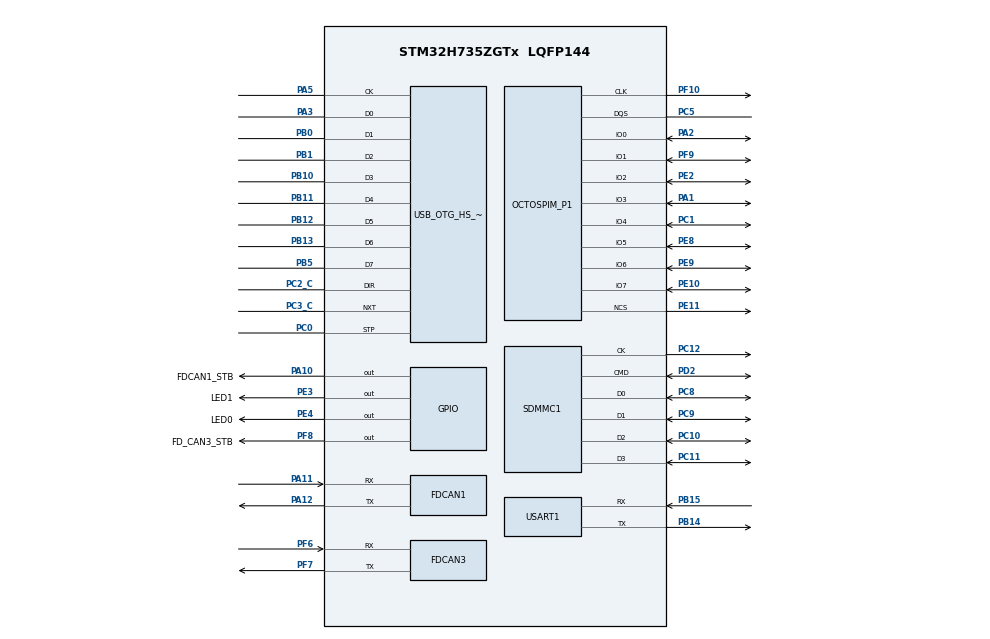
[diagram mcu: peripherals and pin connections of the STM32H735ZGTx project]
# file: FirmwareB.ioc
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Mcu.Family=STM32H7
NVIC.OTG_HS_IRQn=true\:5\:0\:false\:false\:true\:true\:false\:true
PH0-OSC_IN.Signal=RCC_OSC_IN
VP_USB_DEVICE_VS_USB_DEVICE_CDC_HS.Mode=CDC_HS
RCC.CortexFreq_Value=550000000
FATFS._USE_LFN=2
PB10.Mode=Device_HS
RCC.HPRE=RCC_HCLK_DIV2
VP_FATFS_VS_SDIO.Mode=SDIO
PA15(JTDI).Signal=DEBUG_JTDI
PC10.Signal=SDMMC1_D2
PC12.Signal=SDMMC1_CK
RCC.PLLFRACN=6144
PC3_C.Mode=Device_HS
PA13(JTMS/SWDIO).Signal=DEBUG_JTMS-SWDIO
VP_RTC_VS_RTC_Activate.Mode=RTC_Enabled
PA11.Mode=FDCAN_Activate
NVIC.TIM1_UP_IRQn=true\:0\:0\:false\:false\:true\:false\:false\:true
RCC.PLL2FRACN=0
PC5.Mode=OCTOSPI1_Port1_DQS
PB11.Signal=USB_OTG_HS_ULPI_D4
PB13.Signal=USB_OTG_HS_ULPI_D6
PB15.Signal=USART1_RX
PB4(NJTRST).Mode=JTAG_5_pins
USB_OTG_HS.VirtualMode-Device_HS=Device_HS
RCC.SYSCLKSource=RCC_SYSCLKSOURCE_PLLCLK
ProjectManager.StackSize=0x400
VP_FREERTOS_VS_CMSIS_V2.Mode=CMSIS_V2
PA13(JTMS/SWDIO).Mode=JTAG_5_pins
PA12.Signal=FDCAN1_TX
PE11.Mode=OCTOSPI1_Port1_NCS
PF7.Signal=FDCAN3_TX
RCC.HCLKFreq_Value=275000000
PE2.Mode=OCTOSPI1_IOL_Port1L
PC2_C.Signal=USB_OTG_HS_ULPI_DIR
PH0-OSC_IN.Mode=HSE-External-Oscillator
RCC.HSE_VALUE=8000000
RCC.DIVM1=1
RCC.RTCClockSelection=RCC_RTCCLKSOURCE_LSE
PF9.Mode=OCTOSPI1_IOL_Port1L
PC14-OSC32_IN.Mode=LSE-External-Oscillator
PE9.Signal=OCTOSPIM_P1_IO6
PB14.Mode=Asynchronous
VP_SYS_VS_tim1.Mode=TIM1
PB3(JTDO/TRACESWO).Signal=DEBUG_JTDO-SWO
PB5.Mode=Device_HS
PA10.GPIO_Label=FDCAN1_STB
PE4.GPIO_Label=LED0
PC9.Mode=SD_4_bits_Wide_bus
PE2.Signal=OCTOSPIM_P1_IO2
PE4.Signal=GPIO_Output
PE10.Signal=OCTOSPIM_P1_IO7
RCC.APB3Freq_Value=137500000
PH1-OSC_OUT.Mode=HSE-External-Oscillator
Mcu.Package=LQFP144
PB1.Signal=USB_OTG_HS_ULPI_D2
PB12.Mode=Device_HS
NVIC.TimeBase=TIM1_UP_IRQn
RCC.PLL3FRACN=0
RCC.D1PPRE=RCC_APB3_DIV2
PB3(JTDO/TRACESWO).Mode=JTAG_5_pins
NVIC.TimeBaseIP=TIM1
PA10.Signal=GPIO_Output
USB_DEVICE.CLASS_NAME_HS=CDC
PF8.Signal=GPIO_Output
PE9.Mode=OCTOSPI1_IOH_Port1H
PC11.Mode=SD_4_bits_Wide_bus
USB_DEVICE.VirtualModeHS=Cdc_HS
RCC.APB4Freq_Value=137500000
PF10.Mode=O1_P1_CLK
PC5.Signal=OCTOSPIM_P1_DQS
PB13.Mode=Device_HS
PA3.Signal=USB_OTG_HS_ULPI_D0
PA5.Mode=Device_HS
PC15-OSC32_OUT.Mode=LSE-External-Oscillator
RCC.DIVQ1=5
FREERTOS.Tasks01=defaultTask,24,128,StartDefaultTask,Default,NULL,Static,defaultTaskBuffer,defaultTaskControlBlock
FATFS._USE_MUTEX=1
PC11.Signal=SDMMC1_D3
PC8.Signal=SDMMC1_D0
PE10.Mode=OCTOSPI1_IOH_Port1H
PC10.Mode=SD_4_bits_Wide_bus
RCC.D2PPRE2=RCC_APB2_DIV2
RCC.D2PPRE1=RCC_APB1_DIV2
RCC.DIVP1=1
PC0.Signal=USB_OTG_HS_ULPI_STP
PC14-OSC32_IN.Signal=RCC_OSC32_IN
PB4(NJTRST).Signal=DEBUG_JTRST
PC0.Mode=Device_HS
PF8.GPIO_Label=FD_CAN3_STB
PE8.Mode=OCTOSPI1_IOH_Port1H
USART1.VirtualMode-Asynchronous=VM_ASYNC
PA3.Mode=Device_HS
PF7.Mode=FDCAN_Activate
PF6.Signal=FDCAN3_RX
PB11.Mode=Device_HS
ProjectManager.TargetToolchain=STM32CubeIDE
RCC.DIVN1=68
PC2_C.Mode=Device_HS
RCC.USBFreq_Value=110000000
PE11.Signal=OCTOSPIM_P1_NCS
PC15-OSC32_OUT.Signal=RCC_OSC32_OUT
PA1.Signal=OCTOSPIM_P1_IO3
PB10.Signal=USB_OTG_HS_ULPI_D3
PB14.Signal=USART1_TX
PD2.Mode=SD_4_bits_Wide_bus
PA5.Signal=USB_OTG_HS_ULPI_CK
PC12.Mode=SD_4_bits_Wide_bus
PB0.Mode=Device_HS
board=custom
PB15.Mode=Asynchronous
RCC.APB2Freq_Value=137500000
PA1.Mode=OCTOSPI1_IOL_Port1L
FATFS._FS_EXFAT=1
VP_TIM2_VS_ClockSourceINT.Mode=Internal
PE8.Signal=OCTOSPIM_P1_IO5
PF10.Signal=OCTOSPIM_P1_CLK
RCC.ADCFreq_Value=16125000
PH1-OSC_OUT.Signal=RCC_OSC_OUT
PA14(JTCK/SWCLK).Mode=JTAG_5_pins
Mcu.Name=STM32H735ZGTx
PA2.Signal=OCTOSPIM_P1_IO0
PC8.Mode=SD_4_bits_Wide_bus
RCC.SYSCLKFreq_VALUE=550000000
PB5.Signal=USB_OTG_HS_ULPI_D7
PA12.Mode=FDCAN_Activate
VP_OCTOSPI1_VS_hyperbus.Mode=hyperbus_mode
PA11.Signal=FDCAN1_RX
ProjectManager.HeapSize=0x200
PB1.Mode=Device_HS
PF6.Mode=FDCAN_Activate
PF9.Signal=OCTOSPIM_P1_IO1
NVIC.PriorityGroup=NVIC_PRIORITYGROUP_4
PC3_C.Signal=USB_OTG_HS_ULPI_NXT
PE3.Signal=GPIO_Output
PA2.Mode=OCTOSPI1_IOL_Port1L
PE3.GPIO_Label=LED1
RCC.D3PPRE=RCC_APB4_DIV2
PA14(JTCK/SWCLK).Signal=DEBUG_JTCK-SWCLK
PC9.Signal=SDMMC1_D1
PA15(JTDI).Mode=JTAG_5_pins
PD2.Signal=SDMMC1_CMD
RCC.APB1Freq_Value=137500000
PB0.Signal=USB_OTG_HS_ULPI_D1
USB_DEVICE.VirtualMode=Cdc
PC1.Signal=OCTOSPIM_P1_IO4
PB12.Signal=USB_OTG_HS_ULPI_D5
PC1.Mode=OCTOSPI1_IOH_Port1H

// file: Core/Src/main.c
/* USER CODE BEGIN Header */
/**
  ******************************************************************************
  * @file           : main.c
  * @brief          : Main program body
  ******************************************************************************
  * @attention
  *
  * <h2><center>&copy; Copyright (c) 2021 STMicroelectronics.
  * All rights reserved.</center></h2>
  *
  * This software component is licensed by ST under Ultimate Liberty license
  * SLA0044, the "License"; You may not use this file except in compliance with
  * the License. You may obtain a copy of the License at:
  *                             www.st.com/SLA0044
  *
  ******************************************************************************
  */
/* USER CODE END Header */
#include "main.h"
#include "cmsis_os.h"
#include "fatfs.h"
#include "usb_device.h"

typedef StaticTask_t osStaticThreadDef_t;

FDCAN_HandleTypeDef hfdcan1;
FDCAN_HandleTypeDef hfdcan3;

OSPI_HandleTypeDef hospi1;

RTC_HandleTypeDef hrtc;

SD_HandleTypeDef hsd1;

TIM_HandleTypeDef htim2;

UART_HandleTypeDef huart1;

/* Definitions for defaultTask */
osThreadId_t defaultTaskHandle;
uint32_t defaultTaskBuffer[ 128 ];
osStaticThreadDef_t defaultTaskControlBlock;
const osThreadAttr_t defaultTask_attributes = {
  .name = "defaultTask",
  .cb_mem = &defaultTaskControlBlock,
  .cb_size = sizeof(defaultTaskControlBlock),
  .stack_mem = &defaultTaskBuffer[0],
  .stack_size = sizeof(defaultTaskBuffer),
  .priority = (osPriority_t) osPriorityNormal,
};

void SystemClock_Config(void);
static void MX_GPIO_Init(void);
static void MX_FDCAN1_Init(void);
static void MX_FDCAN3_Init(void);
static void MX_OCTOSPI1_Init(void);
static void MX_SDMMC1_SD_Init(void);
static void MX_USART1_UART_Init(void);
static void MX_RTC_Init(void);
static void MX_TIM2_Init(void);
void StartDefaultTask(void *argument);

int main(void)
{

  /* MCU Configuration--------------------------------------------------------*/

  /* Reset of all peripherals, Initializes the Flash interface and the Systick. */
  HAL_Init();

  /* Configure the system clock */
  SystemClock_Config();

  /* Initialize all configured peripherals */
  MX_GPIO_Init();
  MX_FDCAN1_Init();
  MX_FDCAN3_Init();
  MX_OCTOSPI1_Init();
  MX_SDMMC1_SD_Init();
  MX_USART1_UART_Init();
  MX_RTC_Init();
  MX_FATFS_Init();
  MX_TIM2_Init();

  /* Init scheduler */
  osKernelInitialize();

  /* Create the thread(s) */
  /* creation of defaultTask */
  defaultTaskHandle = osThreadNew(StartDefaultTask, NULL, &defaultTask_attributes);

  /* Start scheduler */
  osKernelStart();

  /* We should never get here as control is now taken by the scheduler */
  /* Infinite loop */
  while (1)
  {

  }
}

void SystemClock_Config(void)
{
  RCC_OscInitTypeDef RCC_OscInitStruct = {0};
  RCC_ClkInitTypeDef RCC_ClkInitStruct = {0};

  /** Supply configuration update enable
  */
  HAL_PWREx_ConfigSupply(PWR_LDO_SUPPLY);
  /** Configure the main internal regulator output voltage
  */
  __HAL_PWR_VOLTAGESCALING_CONFIG(PWR_REGULATOR_VOLTAGE_SCALE0);

  while(!__HAL_PWR_GET_FLAG(PWR_FLAG_VOSRDY)) {}
  /** Configure LSE Drive Capability
  */
  HAL_PWR_EnableBkUpAccess();
  __HAL_RCC_LSEDRIVE_CONFIG(RCC_LSEDRIVE_LOW);
  /** Initializes the RCC Oscillators according to the specified parameters
  * in the RCC_OscInitTypeDef structure.
  */
  RCC_OscInitStruct.OscillatorType = RCC_OSCILLATORTYPE_HSE|RCC_OSCILLATORTYPE_LSE;
  RCC_OscInitStruct.HSEState = RCC_HSE_ON;
  RCC_OscInitStruct.LSEState = RCC_LSE_ON;
  RCC_OscInitStruct.PLL.PLLState = RCC_PLL_ON;
  RCC_OscInitStruct.PLL.PLLSource = RCC_PLLSOURCE_HSE;
  RCC_OscInitStruct.PLL.PLLM = 1;
  RCC_OscInitStruct.PLL.PLLN = 68;
  RCC_OscInitStruct.PLL.PLLP = 1;
  RCC_OscInitStruct.PLL.PLLQ = 5;
  RCC_OscInitStruct.PLL.PLLR = 2;
  RCC_OscInitStruct.PLL.PLLRGE = RCC_PLL1VCIRANGE_3;
  RCC_OscInitStruct.PLL.PLLVCOSEL = RCC_PLL1VCOWIDE;
  RCC_OscInitStruct.PLL.PLLFRACN = 6144;
  if (HAL_RCC_OscConfig(&RCC_OscInitStruct) != HAL_OK)
  {
    Error_Handler();
  }
  /** Initializes the CPU, AHB and APB buses clocks
  */
  RCC_ClkInitStruct.ClockType = RCC_CLOCKTYPE_HCLK|RCC_CLOCKTYPE_SYSCLK
                              |RCC_CLOCKTYPE_PCLK1|RCC_CLOCKTYPE_PCLK2
                              |RCC_CLOCKTYPE_D3PCLK1|RCC_CLOCKTYPE_D1PCLK1;
  RCC_ClkInitStruct.SYSCLKSource = RCC_SYSCLKSOURCE_PLLCLK;
  RCC_ClkInitStruct.SYSCLKDivider = RCC_SYSCLK_DIV1;
  RCC_ClkInitStruct.AHBCLKDivider = RCC_HCLK_DIV2;
  RCC_ClkInitStruct.APB3CLKDivider = RCC_APB3_DIV2;
  RCC_ClkInitStruct.APB1CLKDivider = RCC_APB1_DIV2;
  RCC_ClkInitStruct.APB2CLKDivider = RCC_APB2_DIV2;
  RCC_ClkInitStruct.APB4CLKDivider = RCC_APB4_DIV2;

  if (HAL_RCC_ClockConfig(&RCC_ClkInitStruct, FLASH_LATENCY_3) != HAL_OK)
  {
    Error_Handler();
  }
}

static void MX_FDCAN1_Init(void)
{

  hfdcan1.Instance = FDCAN1;
  hfdcan1.Init.FrameFormat = FDCAN_FRAME_CLASSIC;
  hfdcan1.Init.Mode = FDCAN_MODE_NORMAL;
  hfdcan1.Init.AutoRetransmission = DISABLE;
  hfdcan1.Init.TransmitPause = DISABLE;
  hfdcan1.Init.ProtocolException = DISABLE;
  hfdcan1.Init.NominalPrescaler = 1;
  hfdcan1.Init.NominalSyncJumpWidth = 1;
  hfdcan1.Init.NominalTimeSeg1 = 2;
  hfdcan1.Init.NominalTimeSeg2 = 2;
  hfdcan1.Init.DataPrescaler = 1;
  hfdcan1.Init.DataSyncJumpWidth = 1;
  hfdcan1.Init.DataTimeSeg1 = 1;
  hfdcan1.Init.DataTimeSeg2 = 1;
  hfdcan1.Init.MessageRAMOffset = 0;
  hfdcan1.Init.StdFiltersNbr = 0;
  hfdcan1.Init.ExtFiltersNbr = 0;
  hfdcan1.Init.RxFifo0ElmtsNbr = 0;
  hfdcan1.Init.RxFifo0ElmtSize = FDCAN_DATA_BYTES_8;
  hfdcan1.Init.RxFifo1ElmtsNbr = 0;
  hfdcan1.Init.RxFifo1ElmtSize = FDCAN_DATA_BYTES_8;
  hfdcan1.Init.RxBuffersNbr = 0;
  hfdcan1.Init.RxBufferSize = FDCAN_DATA_BYTES_8;
  hfdcan1.Init.TxEventsNbr = 0;
  hfdcan1.Init.TxBuffersNbr = 0;
  hfdcan1.Init.TxFifoQueueElmtsNbr = 0;
  hfdcan1.Init.TxFifoQueueMode = FDCAN_TX_FIFO_OPERATION;
  hfdcan1.Init.TxElmtSize = FDCAN_DATA_BYTES_8;
  if (HAL_FDCAN_Init(&hfdcan1) != HAL_OK)
  {
    Error_Handler();
  }

}

static void MX_FDCAN3_Init(void)
{

  hfdcan3.Instance = FDCAN3;
  hfdcan3.Init.FrameFormat = FDCAN_FRAME_CLASSIC;
  hfdcan3.Init.Mode = FDCAN_MODE_NORMAL;
  hfdcan3.Init.AutoRetransmission = DISABLE;
  hfdcan3.Init.TransmitPause = DISABLE;
  hfdcan3.Init.ProtocolException = DISABLE;
  hfdcan3.Init.NominalPrescaler = 1;
  hfdcan3.Init.NominalSyncJumpWidth = 1;
  hfdcan3.Init.NominalTimeSeg1 = 2;
  hfdcan3.Init.NominalTimeSeg2 = 2;
  hfdcan3.Init.DataPrescaler = 1;
  hfdcan3.Init.DataSyncJumpWidth = 1;
  hfdcan3.Init.DataTimeSeg1 = 1;
  hfdcan3.Init.DataTimeSeg2 = 1;
  hfdcan3.Init.MessageRAMOffset = 0;
  hfdcan3.Init.StdFiltersNbr = 0;
  hfdcan3.Init.ExtFiltersNbr = 0;
  hfdcan3.Init.RxFifo0ElmtsNbr = 0;
  hfdcan3.Init.RxFifo0ElmtSize = FDCAN_DATA_BYTES_8;
  hfdcan3.Init.RxFifo1ElmtsNbr = 0;
  hfdcan3.Init.RxFifo1ElmtSize = FDCAN_DATA_BYTES_8;
  hfdcan3.Init.RxBuffersNbr = 0;
  hfdcan3.Init.RxBufferSize = FDCAN_DATA_BYTES_8;
  hfdcan3.Init.TxEventsNbr = 0;
  hfdcan3.Init.TxBuffersNbr = 0;
  hfdcan3.Init.TxFifoQueueElmtsNbr = 0;
  hfdcan3.Init.TxFifoQueueMode = FDCAN_TX_FIFO_OPERATION;
  hfdcan3.Init.TxElmtSize = FDCAN_DATA_BYTES_8;
  if (HAL_FDCAN_Init(&hfdcan3) != HAL_OK)
  {
    Error_Handler();
  }

}

static void MX_OCTOSPI1_Init(void)
{

  OSPIM_CfgTypeDef sOspiManagerCfg = {0};
  OSPI_HyperbusCfgTypeDef sHyperBusCfg = {0};

  /* OCTOSPI1 parameter configuration*/
  hospi1.Instance = OCTOSPI1;
  hospi1.Init.FifoThreshold = 1;
  hospi1.Init.DualQuad = HAL_OSPI_DUALQUAD_DISABLE;
  hospi1.Init.MemoryType = HAL_OSPI_MEMTYPE_HYPERBUS;
  hospi1.Init.DeviceSize = 32;
  hospi1.Init.ChipSelectHighTime = 1;
  hospi1.Init.FreeRunningClock = HAL_OSPI_FREERUNCLK_DISABLE;
  hospi1.Init.ClockMode = HAL_OSPI_CLOCK_MODE_0;
  hospi1.Init.WrapSize = HAL_OSPI_WRAP_NOT_SUPPORTED;
  hospi1.Init.ClockPrescaler = 1;
  hospi1.Init.SampleShifting = HAL_OSPI_SAMPLE_SHIFTING_NONE;
  hospi1.Init.DelayHoldQuarterCycle = HAL_OSPI_DHQC_DISABLE;
  hospi1.Init.ChipSelectBoundary = 1;
  hospi1.Init.ClkChipSelectHighTime = 0;
  hospi1.Init.DelayBlockBypass = HAL_OSPI_DELAY_BLOCK_BYPASSED;
  hospi1.Init.MaxTran = 0;
  hospi1.Init.Refresh = 0;
  if (HAL_OSPI_Init(&hospi1) != HAL_OK)
  {
    Error_Handler();
  }
  sOspiManagerCfg.ClkPort = 1;
  sOspiManagerCfg.DQSPort = 1;
  sOspiManagerCfg.NCSPort = 1;
  sOspiManagerCfg.IOLowPort = HAL_OSPIM_IOPORT_1_LOW;
  sOspiManagerCfg.IOHighPort = HAL_OSPIM_IOPORT_1_HIGH;
  if (HAL_OSPIM_Config(&hospi1, &sOspiManagerCfg, HAL_OSPI_TIMEOUT_DEFAULT_VALUE) != HAL_OK)
  {
    Error_Handler();
  }
  sHyperBusCfg.RWRecoveryTime = 0;
  sHyperBusCfg.AccessTime = 0;
  sHyperBusCfg.WriteZeroLatency = HAL_OSPI_NO_LATENCY_ON_WRITE;
  sHyperBusCfg.LatencyMode = HAL_OSPI_VARIABLE_LATENCY;
  if (HAL_OSPI_HyperbusCfg(&hospi1, &sHyperBusCfg, HAL_OSPI_TIMEOUT_DEFAULT_VALUE) != HAL_OK)
  {
    Error_Handler();
  }

}

static void MX_RTC_Init(void)
{

  /** Initialize RTC Only
  */
  hrtc.Instance = RTC;
  hrtc.Init.HourFormat = RTC_HOURFORMAT_24;
  hrtc.Init.AsynchPrediv = 127;
  hrtc.Init.SynchPrediv = 255;
  hrtc.Init.OutPut = RTC_OUTPUT_DISABLE;
  hrtc.Init.OutPutPolarity = RTC_OUTPUT_POLARITY_HIGH;
  hrtc.Init.OutPutType = RTC_OUTPUT_TYPE_OPENDRAIN;
  hrtc.Init.OutPutRemap = RTC_OUTPUT_REMAP_NONE;
  if (HAL_RTC_Init(&hrtc) != HAL_OK)
  {
    Error_Handler();
  }

}

static void MX_SDMMC1_SD_Init(void)
{

  hsd1.Instance = SDMMC1;
  hsd1.Init.ClockEdge = SDMMC_CLOCK_EDGE_RISING;
  hsd1.Init.ClockPowerSave = SDMMC_CLOCK_POWER_SAVE_DISABLE;
  hsd1.Init.BusWide = SDMMC_BUS_WIDE_4B;
  hsd1.Init.HardwareFlowControl = SDMMC_HARDWARE_FLOW_CONTROL_DISABLE;
  hsd1.Init.ClockDiv = 0;
  hsd1.Init.TranceiverPresent = SDMMC_TRANSCEIVER_NOT_PRESENT;

}

static void MX_TIM2_Init(void)
{

  TIM_ClockConfigTypeDef sClockSourceConfig = {0};
  TIM_MasterConfigTypeDef sMasterConfig = {0};

  htim2.Instance = TIM2;
  htim2.Init.Prescaler = 0;
  htim2.Init.CounterMode = TIM_COUNTERMODE_UP;
  htim2.Init.Period = 4294967295;
  htim2.Init.ClockDivision = TIM_CLOCKDIVISION_DIV1;
  htim2.Init.AutoReloadPreload = TIM_AUTORELOAD_PRELOAD_DISABLE;
  if (HAL_TIM_Base_Init(&htim2) != HAL_OK)
  {
    Error_Handler();
  }
  sClockSourceConfig.ClockSource = TIM_CLOCKSOURCE_INTERNAL;
  if (HAL_TIM_ConfigClockSource(&htim2, &sClockSourceConfig) != HAL_OK)
  {
    Error_Handler();
  }
  sMasterConfig.MasterOutputTrigger = TIM_TRGO_RESET;
  sMasterConfig.MasterSlaveMode = TIM_MASTERSLAVEMODE_DISABLE;
  if (HAL_TIMEx_MasterConfigSynchronization(&htim2, &sMasterConfig) != HAL_OK)
  {
    Error_Handler();
  }

}

static void MX_USART1_UART_Init(void)
{

  huart1.Instance = USART1;
  huart1.Init.BaudRate = 115200;
  huart1.Init.WordLength = UART_WORDLENGTH_8B;
  huart1.Init.StopBits = UART_STOPBITS_1;
  huart1.Init.Parity = UART_PARITY_NONE;
  huart1.Init.Mode = UART_MODE_TX_RX;
  huart1.Init.HwFlowCtl = UART_HWCONTROL_NONE;
  huart1.Init.OverSampling = UART_OVERSAMPLING_16;
  huart1.Init.OneBitSampling = UART_ONE_BIT_SAMPLE_DISABLE;
  huart1.Init.ClockPrescaler = UART_PRESCALER_DIV1;
  huart1.AdvancedInit.AdvFeatureInit = UART_ADVFEATURE_NO_INIT;
  if (HAL_UART_Init(&huart1) != HAL_OK)
  {
    Error_Handler();
  }
  if (HAL_UARTEx_SetTxFifoThreshold(&huart1, UART_TXFIFO_THRESHOLD_1_8) != HAL_OK)
  {
    Error_Handler();
  }
  if (HAL_UARTEx_SetRxFifoThreshold(&huart1, UART_RXFIFO_THRESHOLD_1_8) != HAL_OK)
  {
    Error_Handler();
  }
  if (HAL_UARTEx_DisableFifoMode(&huart1) != HAL_OK)
  {
    Error_Handler();
  }

}

static void MX_GPIO_Init(void)
{
  GPIO_InitTypeDef GPIO_InitStruct = {0};

  /* GPIO Ports Clock Enable */
  __HAL_RCC_GPIOE_CLK_ENABLE();
  __HAL_RCC_GPIOC_CLK_ENABLE();
  __HAL_RCC_GPIOF_CLK_ENABLE();
  __HAL_RCC_GPIOH_CLK_ENABLE();
  __HAL_RCC_GPIOA_CLK_ENABLE();
  __HAL_RCC_GPIOB_CLK_ENABLE();
  __HAL_RCC_GPIOD_CLK_ENABLE();

  /*Configure GPIO pin Output Level */
  HAL_GPIO_WritePin(GPIOE, LED1_Pin|LED0_Pin, GPIO_PIN_RESET);

  /*Configure GPIO pin Output Level */
  HAL_GPIO_WritePin(FD_CAN3_STB_GPIO_Port, FD_CAN3_STB_Pin, GPIO_PIN_RESET);

  /*Configure GPIO pin Output Level */
  HAL_GPIO_WritePin(FDCAN1_STB_GPIO_Port, FDCAN1_STB_Pin, GPIO_PIN_RESET);

  /*Configure GPIO pins : LED1_Pin LED0_Pin */
  GPIO_InitStruct.Pin = LED1_Pin|LED0_Pin;
  GPIO_InitStruct.Mode = GPIO_MODE_OUTPUT_PP;
  GPIO_InitStruct.Pull = GPIO_NOPULL;
  GPIO_InitStruct.Speed = GPIO_SPEED_FREQ_LOW;
  HAL_GPIO_Init(GPIOE, &GPIO_InitStruct);

  /*Configure GPIO pin : FD_CAN3_STB_Pin */
  GPIO_InitStruct.Pin = FD_CAN3_STB_Pin;
  GPIO_InitStruct.Mode = GPIO_MODE_OUTPUT_PP;
  GPIO_InitStruct.Pull = GPIO_NOPULL;
  GPIO_InitStruct.Speed = GPIO_SPEED_FREQ_LOW;
  HAL_GPIO_Init(FD_CAN3_STB_GPIO_Port, &GPIO_InitStruct);

  /*Configure GPIO pin : FDCAN1_STB_Pin */
  GPIO_InitStruct.Pin = FDCAN1_STB_Pin;
  GPIO_InitStruct.Mode = GPIO_MODE_OUTPUT_PP;
  GPIO_InitStruct.Pull = GPIO_NOPULL;
  GPIO_InitStruct.Speed = GPIO_SPEED_FREQ_LOW;
  HAL_GPIO_Init(FDCAN1_STB_GPIO_Port, &GPIO_InitStruct);

}

void StartDefaultTask(void *argument)
{
  /* init code for USB_DEVICE */
  MX_USB_DEVICE_Init();
  /* USER CODE BEGIN 5 */
  /* Infinite loop */
  for(;;)
  {
    osDelay(200);
    HAL_GPIO_TogglePin(LED1_GPIO_Port,LED1_Pin);
  }
  /* USER CODE END 5 */
}

 /**
  * @brief  Period elapsed callback in non blocking mode
  * @note   This function is called  when TIM1 interrupt took place, inside
  * HAL_TIM_IRQHandler(). It makes a direct call to HAL_IncTick() to increment
  * a global variable "uwTick" used as application time base.
  * @param  htim : TIM handle
  * @retval None
  */
void HAL_TIM_PeriodElapsedCallback(TIM_HandleTypeDef *htim)
{
  if (htim->Instance == TIM1) {
    HAL_IncTick();
  }
}

void Error_Handler(void)
{
  /* USER CODE BEGIN Error_Handler_Debug */
  /* User can add his own implementation to report the HAL error return state */
  __disable_irq();
  HAL_GPIO_WritePin(LED0_GPIO_Port,LED0_Pin,GPIO_PIN_SET);
  while (1)
  {
  }
  /* USER CODE END Error_Handler_Debug */
}

/************************ (C) COPYRIGHT STMicroelectronics *****END OF FILE****/
